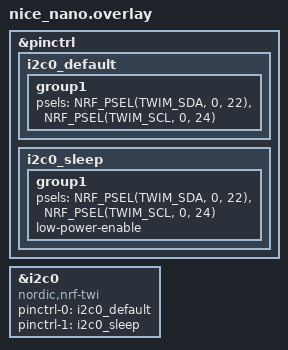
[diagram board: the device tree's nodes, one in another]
#include <dt-bindings/pinctrl/nrf-pinctrl.h>

&pinctrl {
	i2c0_default: i2c0_default {
		group1 {
			psels = <NRF_PSEL(TWIM_SDA, 0, 22)>,  /* D4/A6 */
				<NRF_PSEL(TWIM_SCL, 0, 24)>;   /* D5 */
		};
	};
	i2c0_sleep: i2c0_sleep {
		group1 {
			psels = <NRF_PSEL(TWIM_SDA, 0, 22)>,
				<NRF_PSEL(TWIM_SCL, 0, 24)>;
			low-power-enable;
		};
	};
};

&i2c0 {
	compatible = "nordic,nrf-twi";
	pinctrl-0 = <&i2c0_default>;
	pinctrl-1 = <&i2c0_sleep>;
	pinctrl-names = "default", "sleep";
};
